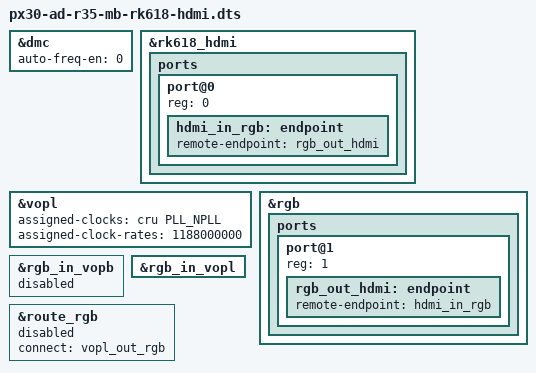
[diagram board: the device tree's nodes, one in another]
// SPDX-License-Identifier: GPL-2.0
/*
 * Copyright (c) 2018 Fuzhou Rockchip Electronics Co., Ltd
 */

/dts-v1/;
#include "px30-ad-r35-mb.dtsi"

&dmc {
	auto-freq-en = <0>;
};

&rk618_hdmi {
	status = "okay";

	ports {
		#address-cells = <1>;
		#size-cells = <0>;

		port@0 {
			reg = <0>;

			hdmi_in_rgb: endpoint {
				remote-endpoint = <&rgb_out_hdmi>;
			};
		};
	};
};

&vopl {
	assigned-clocks = <&cru PLL_NPLL>;
	assigned-clock-rates = <1188000000>;
};

&rgb {
	status = "okay";

	ports {
		port@1 {
			reg = <1>;

			rgb_out_hdmi: endpoint {
				remote-endpoint = <&hdmi_in_rgb>;
			};
		};
	};
};

&rgb_in_vopb {
	status = "disabled";
};

&rgb_in_vopl {
	status = "okay";
};

&route_rgb {
	connect = <&vopl_out_rgb>;
	status = "disabled";
};
